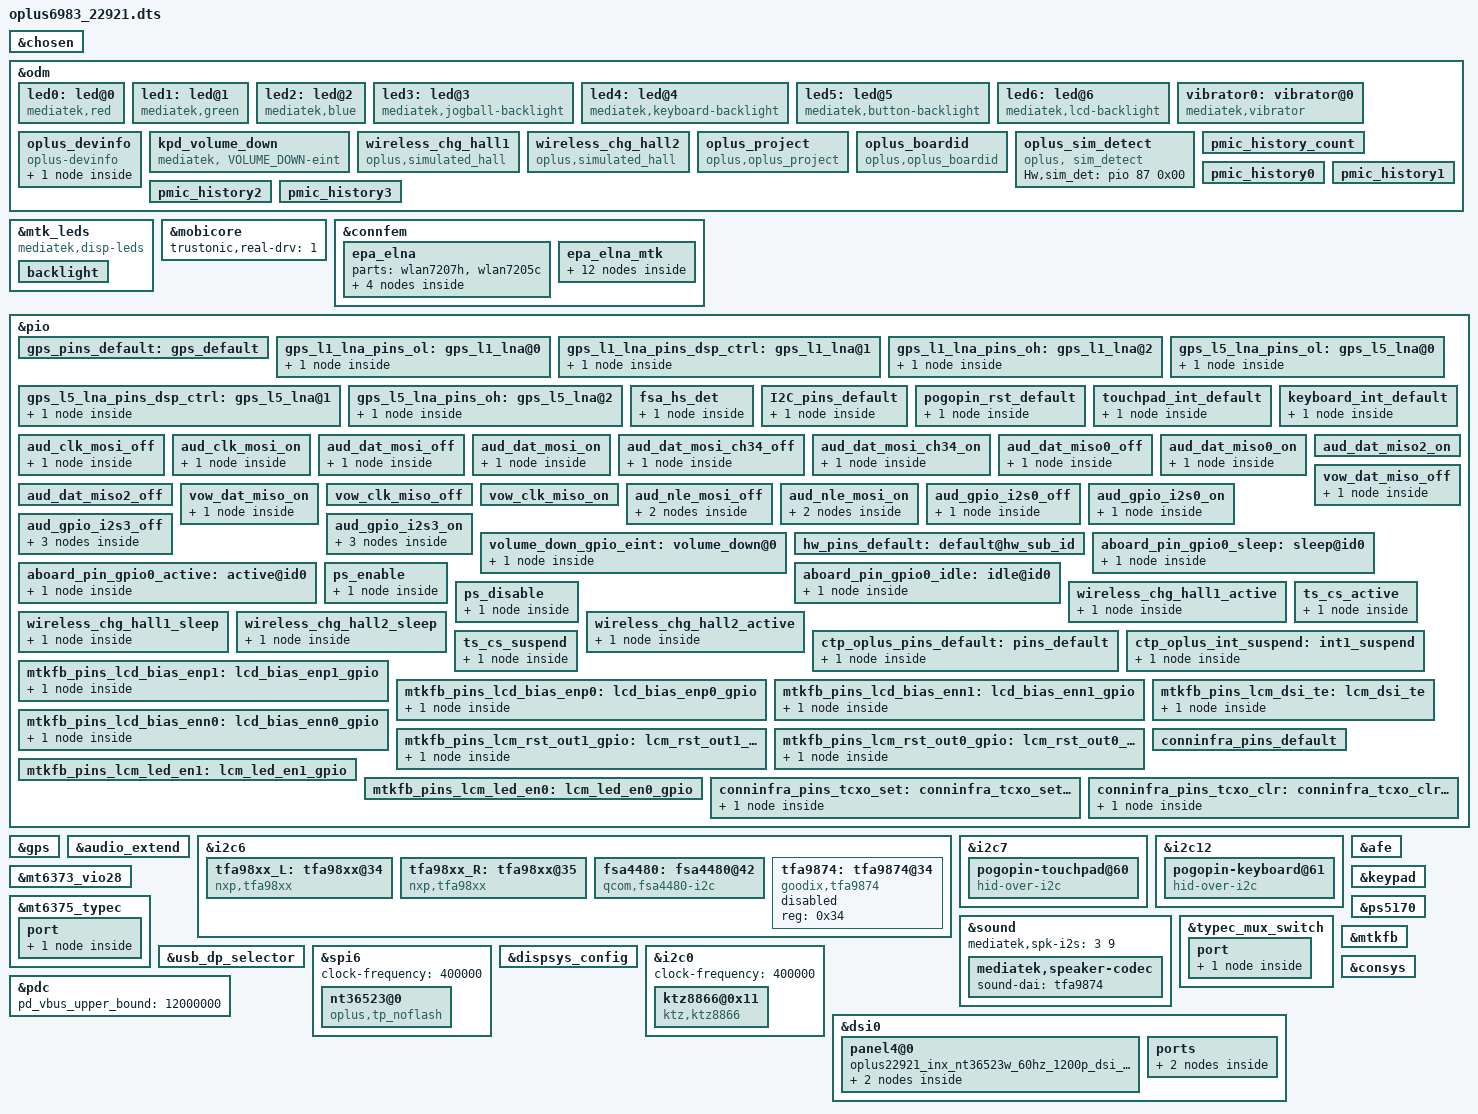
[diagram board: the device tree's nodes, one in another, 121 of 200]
// SPDX-License-Identifier: (GPL-2.0 OR MIT)
/*
 * Copyright (C) 2020 MediaTek Inc.
 */
/dts-v1/;
/plugin/;
#include <dt-bindings/interrupt-controller/arm-gic.h>
#include <dt-bindings/interrupt-controller/irq.h>
#include <dt-bindings/pinctrl/mt6983-pinfunc.h>
#include <dt-bindings/clock/mt6983-clk.h>
#include <dt-bindings/phy/phy.h>
#include "mediatek/oplus-22921-tp.dtsi"
//#ifdef OPLUS_FEATURE_CHG_BASIC
#include "mediatek/oplus_charge_22921.dtsi"
//#endif

//#ifdef OPLUS_FEATURE_SENSOR

#include "mediatek/oplus_sensor_22921.dtsi"
//#endif

//#ifdef OPLUS_FEATURE_NFC_BRINGUP
//#include "mediatek/nfc/mt6983_diting_21007_sn100.dtsi"
//#endif OPLUS_FEATURE_NFC_BRINGUP
&chosen {
	bootargs_ext = "loglevel=8 \
	androidboot.hardware=mt6983";
};

&odm {
	led0:led@0 {
		compatible = "mediatek,red";
		led_mode = <0>;
		data = <1>;
		pwm_config = <0 0 0 0 0>;
	};
	led1:led@1 {
		compatible = "mediatek,green";
		led_mode = <0>;
		data = <1>;
		pwm_config = <0 0 0 0 0>;
	};
	led2:led@2 {
		compatible = "mediatek,blue";
		led_mode = <0>;
		data = <1>;
		pwm_config = <0 0 0 0 0>;
	};
	led3:led@3 {
		compatible = "mediatek,jogball-backlight";
		led_mode = <0>;
		data = <1>;
		pwm_config = <0 0 0 0 0>;
	};
	led4:led@4 {
		compatible = "mediatek,keyboard-backlight";
		led_mode = <0>;
		data = <1>;
		pwm_config = <0 0 0 0 0>;
	};
	led5:led@5 {
		compatible = "mediatek,button-backlight";
		led_mode = <0>;
		data = <1>;
		pwm_config = <0 0 0 0 0>;
	};
	led6:led@6 {
		compatible = "mediatek,lcd-backlight";
		led_mode = <4>;
		data = <1>;
		pwm_config = <0 1 0 0 0>;
	};
	vibrator0:vibrator@0 {
		compatible = "mediatek,vibrator";
		vib_timer = <25>;
		vib_limit = <9>;
		vib_vol= <9>;
	};
};

&mtk_leds {
	compatible = "mediatek,disp-leds";
	backlight {
		label = "lcd-backlight";
		led_mode = <4>;
		max-brightness = <10239>;
		max-hw-brightness = <10239>;
		led-bits = <13>;
		};
};

/*Trustonic Mobicore real driver*/
&mobicore {
	trustonic,real-drv=<1>;
};

&connfem {
#if 1 /* Enable epa_elna node to support Wifi & BT ePA/eLNA FEM on customer load */
	epa_elna {
		parts = <&wlan7207h &wlan7205c>;

		wifi {
			flags-0 {
				/* open-loop; */
			};
		};

		bt {
			flags-0 {
				/* choose one of: epa_elna / epa / elna / bypass */
				epa_elna;
			};
		};
	};
#endif

	epa_elna_mtk {
		parts = <&nofem &nofem>,		/* [0]iPA/iLNA */
			<&wlan7207h &wlan7205c_laa>,	/* [1]ePA/eLNA - Open Loop, LAA 4x4 */
			<&wlan7207h &wlan7205c>,	/* [2]ePA/eLNA - Open Loop */
			<&wlan7207h &wlan7205c>,	/* [3]ePA/eLNA - Closed-Loop */
			<&wlan7207h &wlan7205c_laa>,	/* [4]ePA/eLNA - Closed-Loop, LAA 4x4 */
			<&wlan7207h &wlan7205c>,	/* [5]ePA/eLNA - Closed-Loop + BT Bypass */
			<&wlan7207h &wlan7205c>;	/* [6]ePA/eLNA - Open Loop + BT Bypass */

		hwid = <&pio 203 0x00>;

		wifi {
			flags-1 {
				open-loop;
				laa;
			};
			flags-2 {
				open-loop;
			};
			flags-4 {
				laa;
			};
			flags-6 {
				open-loop;
			};
		};

		bt {
			flags-1 {
				/* choose one of: epa_elna / epa / elna / bypass */
				epa_elna;
			};
			flags-2 {
				epa_elna;
			};
			flags-3 {
				epa_elna;
			};
			flags-4 {
				epa_elna;
			};
			flags-5 {
				bypass;
			};
			flags-6 {
				bypass;
			};
		};
	};
};

/* GPS GPIO standardization start */
&pio {
	gps_pins_default: gps_default {
	};

	gps_l1_lna_pins_ol: gps_l1_lna@0 {
		pins_cmd_dat {
			pinmux = <PINMUX_GPIO16__FUNC_GPIO16>;
			output-low;
		};
	};
	gps_l1_lna_pins_dsp_ctrl: gps_l1_lna@1 {
		pins_cmd_dat {
			pinmux = <PINMUX_GPIO16__FUNC_GPS_L1_ELNA_EN>;
		};
	};
	gps_l1_lna_pins_oh: gps_l1_lna@2 {
		pins_cmd_dat {
			pinmux = <PINMUX_GPIO16__FUNC_GPIO16>;
			output-high;
		};
	};

	gps_l5_lna_pins_ol: gps_l5_lna@0 {
		pins_cmd_dat {
			pinmux = <PINMUX_GPIO17__FUNC_GPIO17>;
			output-low;
		};
	};
	gps_l5_lna_pins_dsp_ctrl: gps_l5_lna@1 {
		pins_cmd_dat {
			pinmux = <PINMUX_GPIO17__FUNC_GPS_L5_ELNA_EN>;
		};
	};
	gps_l5_lna_pins_oh: gps_l5_lna@2 {
		pins_cmd_dat {
			pinmux = <PINMUX_GPIO17__FUNC_GPIO17>;
			output-high;
		};
	};
};

&gps {
	pinctrl-names = "default",
		"gps_l1_lna_disable",
		"gps_l1_lna_dsp_ctrl",
		"gps_l1_lna_enable",
		"gps_l5_lna_disable",
		"gps_l5_lna_dsp_ctrl",
		"gps_l5_lna_enable";
	pinctrl-0 = <&gps_pins_default>;
	pinctrl-1 = <&gps_l1_lna_pins_ol>;
	pinctrl-2 = <&gps_l1_lna_pins_dsp_ctrl>;
	pinctrl-3 = <&gps_l1_lna_pins_oh>;
	pinctrl-4 = <&gps_l5_lna_pins_ol>;
	pinctrl-5 = <&gps_l5_lna_pins_dsp_ctrl>;
	pinctrl-6 = <&gps_l5_lna_pins_oh>;
	status = "okay";
};
/* GPS GPIO standardization end */

//#ifdef OPLUS_ARCH_EXTENDS
&audio_extend {
	//for nxp speaker
	oplus,speaker-vendor = "nxp";
	oplus,speaker-i2s-id = <3>;
	oplus,speaker-i2s-id-in = <0>;
	oplus,speaker-codec-name = "tfa98xx.6-0034","tfa98xx.6-0035";
	oplus,speaker-codec-dai-name = "tfa98xx-aif-6-34","tfa98xx-aif-6-35";
};

&i2c6 {
	clock-frequency = <400000>;
	pinctrl-names = "default";
	pinctrl-0 = <&I2C_pins_default>;
	status = "okay";
	tfa98xx_L: tfa98xx@34 {
		compatible = "nxp,tfa98xx";
		reg = <0x34>;
		reset-gpio = <&pio 2 0>;
		tfa_min_range = <5000>;
		tfa_max_range = <8000>;
		tfa_channel = <0>;
		status = "okay";
	};

	tfa98xx_R: tfa98xx@35 {
		compatible = "nxp,tfa98xx";
		reg = <0x35>;
		reset-gpio = <&pio 1 0>;
		tfa_min_range = <5000>;
		tfa_max_range = <8000>;
		tfa_channel = <1>;
		status = "okay";
	};
};

&i2c6 {
	fsa4480: fsa4480@42 {
		compatible = "qcom,fsa4480-i2c";
		reg = <0x42>;
		fsa_audio-supply = <&mt6373_vio28>;
		pinctrl-names = "default";
		pinctrl-0 = <&fsa_hs_det>;
		fsa4480,hs-det-gpio = <&pio 98 0>;
	};
};

&pio {
	fsa_hs_det: fsa_hs_det {
		pins_cmd_dat {
			pinmux = <PINMUX_GPIO98__FUNC_GPIO98>;
			slew-rate = <1>;  /*direction 0:in, 1:out*/
			output-high;
		};
	};
};

&pio {
	I2C_pins_default: I2C_pins_default {
		pins_cmd_dat {
			pinmux = <PINMUX_GPIO49__FUNC_SCP_SCL1>,
					<PINMUX_GPIO50__FUNC_SCP_SDA1>;
			/* 0x0:75k 0x1:3k 0x2:5k 0x3:1.5k */
			/* 0x4:10k 0x5:2k 0x6:4k 0x7:1k */
			bias-pull-up = <MTK_PULL_SET_RSEL_001>;
		};
	};
};
//#endif /*OPLUS_ARCH_EXTENDS*/

&i2c6 {
	tfa9874: tfa9874@34 {
		compatible = "goodix,tfa9874";
		#sound-dai-cells = <0>;
		reg = <0x34>;
		status = "disabled";
	};
};
/*
&i2c6 {
	spk1: speaker_amp@5c {
		compatible = "richtek,rt5512";
		#sound-dai-cells = <0>;
		reg = <0x5c>;
		status = "okay";
		sound-name-prefix = "Left";
	};

	spk2: speaker_amp@5d {
		compatible = "richtek,rt5512";
		#sound-dai-cells = <0>;
		reg = <0x5d>;
		status = "okay";
		sound-name-prefix = "Right";
	};
};*/

&i2c7 {
	status = "okay";
	pogopin-touchpad@60 {
		status = "ok";
		compatible = "hid-over-i2c";
		reg = <0x60>;
		pinctrl-names = "default";
		pinctrl-0 = <&touchpad_int_default &pogopin_rst_default>;

		vdd-supply = <&mt6373_vcn33_3>;
		post-power-on-delay-ms = <100>;

		interrupt-parent = <&pio>;
		interrupts = <35 0x2008>;

		hid-descr-addr = <0x01>;
	};
};

&i2c12 {
	status = "okay";
	pogopin-keyboard@61 {
		status = "ok";
		compatible = "hid-over-i2c";
		reg = <0x61>;
		pinctrl-names = "default";
		pinctrl-0 = <&keyboard_int_default>;

		vdd-supply = <&mt6373_vcn33_3>;
		post-power-on-delay-ms = <100>;

		interrupt-parent = <&pio>;
		interrupts = <34 0x2008>;

		hid-descr-addr = <0x01>;
	};
};

&pio {
	pogopin_rst_default: pogopin_rst_default {
		pins_cmd_dat {
			pinmux = <PINMUX_GPIO203__FUNC_GPIO203>;
			output-high;
		};
	};
	touchpad_int_default: touchpad_int_default {
		pins_cmd_dat {
			pinmux = <PINMUX_GPIO35__FUNC_GPIO35>;
			input-enable;
			bias-pull-up;
		};
	};
	keyboard_int_default: keyboard_int_default {
		pins_cmd_dat {
			pinmux = <PINMUX_GPIO34__FUNC_GPIO34>;
			input-enable;
			bias-pull-up;
		};
	};
};

&sound {
	mediatek,spk-i2s = <3 9>;
	mediatek,speaker-codec {
		sound-dai = <&tfa9874>;
	};
};

/* AUDIO GPIO standardization start */
&afe {
	pinctrl-names = "aud_clk_mosi_off",
			"aud_clk_mosi_on",
			"aud_dat_mosi_off",
			"aud_dat_mosi_on",
			"aud_dat_mosi_ch34_off",
			"aud_dat_mosi_ch34_on",
			"aud_dat_miso0_off",
			"aud_dat_miso0_on",
			"aud_dat_miso2_off",
			"aud_dat_miso2_on",
			"vow_dat_miso_off",
			"vow_dat_miso_on",
			"vow_clk_miso_off",
			"vow_clk_miso_on",
			"aud_gpio_i2s0_off",
			"aud_gpio_i2s0_on",
			"aud_gpio_i2s3_off",
			"aud_gpio_i2s3_on";
	pinctrl-0 = <&aud_clk_mosi_off>;
	pinctrl-1 = <&aud_clk_mosi_on>;
	pinctrl-2 = <&aud_dat_mosi_off>;
	pinctrl-3 = <&aud_dat_mosi_on>;
	pinctrl-4 = <&aud_dat_mosi_ch34_off>;
	pinctrl-5 = <&aud_dat_mosi_ch34_on>;
	pinctrl-6 = <&aud_dat_miso0_off>;
	pinctrl-7 = <&aud_dat_miso0_on>;
	pinctrl-8 = <&aud_dat_miso2_off>;
	pinctrl-9 = <&aud_dat_miso2_on>;
	pinctrl-10 = <&vow_dat_miso_off>;
	pinctrl-11 = <&vow_dat_miso_on>;
	pinctrl-12 = <&vow_clk_miso_off>;
	pinctrl-13 = <&vow_clk_miso_on>;
	pinctrl-14 = <&aud_gpio_i2s0_off>;
	pinctrl-15 = <&aud_gpio_i2s0_on>;
	pinctrl-16 = <&aud_gpio_i2s3_off>;
	pinctrl-17 = <&aud_gpio_i2s3_on>;
};
&pio {
	aud_clk_mosi_off: aud_clk_mosi_off {
		pins_cmd0_dat {
			pinmux = <PINMUX_GPIO51__FUNC_GPIO51>;
			input-enable;
			bias-pull-down;
		};
	};
	aud_clk_mosi_on: aud_clk_mosi_on {
		pins_cmd0_dat {
			pinmux = <PINMUX_GPIO51__FUNC_AUD_CLK_MOSI>;
			input-schmitt-enable;
			bias-disable;
		};
	};
	aud_dat_mosi_off: aud_dat_mosi_off {
		pins_cmd1_dat {
			pinmux = <PINMUX_GPIO52__FUNC_GPIO52>;
			input-enable;
			bias-pull-down;
		};
	};
	aud_dat_mosi_on: aud_dat_mosi_on {
		pins_cmd1_dat {
			pinmux = <PINMUX_GPIO52__FUNC_AUD_DAT_MOSI0>;
			input-schmitt-enable;
			bias-disable;
		};
	};
	aud_dat_mosi_ch34_off: aud_dat_mosi_ch34_off {
		pins_cmd1_dat {
			pinmux = <PINMUX_GPIO53__FUNC_GPIO53>;
			input-enable;
			bias-pull-down;
		};
	};
	aud_dat_mosi_ch34_on: aud_dat_mosi_ch34_on {
		pins_cmd1_dat {
			pinmux = <PINMUX_GPIO53__FUNC_AUD_DAT_MOSI1>;
			input-schmitt-enable;
			bias-disable;
		};
	};
	aud_dat_miso0_off: aud_dat_miso0_off {
		pins_cmd1_dat {
			pinmux = <PINMUX_GPIO54__FUNC_GPIO54>;
			input-enable;
			bias-pull-down;
		};
	};
	aud_dat_miso0_on: aud_dat_miso0_on {
		pins_cmd1_dat {
			pinmux = <PINMUX_GPIO54__FUNC_AUD_DAT_MISO0>;
			input-schmitt-enable;
			bias-disable;
		};
	};
	aud_dat_miso2_off: aud_dat_miso2_off {
	/* NC GPIO0,GPIO1,GPIO2 */
	};
	aud_dat_miso2_on: aud_dat_miso2_on {
	/* NC GPIO0,GPIO1,GPIO2 */
	};
	vow_dat_miso_off: vow_dat_miso_off {
		pins_cmd1_dat {
			pinmux = <PINMUX_GPIO54__FUNC_GPIO54>;
			input-enable;
			bias-pull-down;
		};
	};
	vow_dat_miso_on: vow_dat_miso_on {
		pins_cmd1_dat {
			pinmux = <PINMUX_GPIO54__FUNC_VOW_DAT_MISO>;
			input-schmitt-enable;
			bias-disable;
		};
	};
	vow_clk_miso_off: vow_clk_miso_off {
	/* NC GPIO0,GPIO1,GPIO2 */
	};
	vow_clk_miso_on: vow_clk_miso_on {
	/* NC GPIO0,GPIO1,GPIO2 */
	};
	aud_nle_mosi_off: aud_nle_mosi_off {
		pins_cmd1_dat {
			pinmux = <PINMUX_GPIO49__FUNC_GPIO49>;
			input-enable;
			bias-pull-down;
		};
		pins_cmd2_dat {
			pinmux = <PINMUX_GPIO50__FUNC_GPIO50>;
			input-enable;
			bias-pull-down;
		};
	};
	aud_nle_mosi_on: aud_nle_mosi_on {
		pins_cmd1_dat {
			pinmux = <PINMUX_GPIO49__FUNC_AUD_NLE_MOSI0>;
			input-schmitt-enable;
			bias-disable;
		};
		pins_cmd2_dat {
			pinmux = <PINMUX_GPIO50__FUNC_AUD_NLE_MOSI1>;
			input-schmitt-enable;
			bias-disable;
		};
	};
	aud_gpio_i2s0_off: aud_gpio_i2s0_off {
		pins_cmd1_dat {
			pinmux = <PINMUX_GPIO28__FUNC_GPIO28>;
			input-enable;
			bias-pull-down;
		};
	};
	aud_gpio_i2s0_on: aud_gpio_i2s0_on {
		pins_cmd1_dat {
			pinmux = <PINMUX_GPIO28__FUNC_I2S0_DI>;
			input-schmitt-enable;
			bias-disable;
		};
	};
	aud_gpio_i2s3_off: aud_gpio_i2s3_off {
		pins_cmd1_dat {
			pinmux = <PINMUX_GPIO26__FUNC_GPIO26>;
			input-enable;
			bias-pull-down;
		};
		pins_cmd2_dat {
			pinmux = <PINMUX_GPIO27__FUNC_GPIO27>;
			input-enable;
			bias-pull-down;
		};
		pins_cmd3_dat {
			pinmux = <PINMUX_GPIO29__FUNC_GPIO29>;
			input-enable;
			bias-pull-down;
		};
	};
	aud_gpio_i2s3_on: aud_gpio_i2s3_on {
		pins_cmd1_dat {
			pinmux = <PINMUX_GPIO26__FUNC_I2S3_BCK>;
			input-schmitt-enable;
			bias-disable;
		};
		pins_cmd2_dat {
			pinmux = <PINMUX_GPIO27__FUNC_I2S3_LRCK>;
			input-schmitt-enable;
			bias-disable;
		};
		pins_cmd3_dat {
			pinmux = <PINMUX_GPIO29__FUNC_I2S3_DO>;
			input-schmitt-enable;
			bias-disable;
		};
	};
};
/* AUDIO GPIO standardization end */

&mt6373_vio28 {
       regulator-min-microvolt = <3000000>;
       regulator-max-microvolt = <3000000>;
};


&odm {
//#ifdef OPLUS_FEATURE_TP_BASIC
        oplus_devinfo:oplus_devinfo {
                compatible = "oplus-devinfo";
                pinctrl-names = "default", "aboard_gpio0_sleep", "aboard_gpio0_active", "aboard_gpio0_idle";
                pinctrl-0 = <&hw_pins_default>;
                pinctrl-1 = <&aboard_pin_gpio0_sleep>;
                pinctrl-2 = <&aboard_pin_gpio0_active>;
                pinctrl-3 = <&aboard_pin_gpio0_idle>;
                main-sub {
                        use_tristate_gpio;
                        compatible = "hw-match, main-sub";
                        aboard-gpio0 = <&pio 206 0x00>;
                        aboard-patterns = <0 1>;        /*0[high-resistance] 1[pull-down] 2[pull-up]*/
                        /*main board*/
                        match-projects = <22921 22971>;
                };
        };

	kpd_volume_down:kpd_volume_down {
                compatible = "mediatek, VOLUME_DOWN-eint";
                interrupt-parent = <&pio>;
                interrupts = <12 IRQ_TYPE_EDGE_FALLING 12 0>;
                debounce = <32000>;
                status = "okay";
        };

//#endif OPLUS_FEATURE_TP_BASIC
};

&keypad {
        keypad,volume-down = <&pio 12 0x00>;
        pinctrl-names = "volume_down_as_int";
        pinctrl-0 = <&volume_down_gpio_eint>;
        status = "okay";
};

&pio {
        volume_down_gpio_eint:volume_down@0{
                pins_cmd_dat {
                        pinmux = <PINMUX_GPIO12__FUNC_GPIO12>;
                        slew-rate = <0>;  /*direction 0:in, 1:out*/
                        input-enable;
                };
        };
};

&pio {
        hw_pins_default:default@hw_sub_id {
        };

        aboard_pin_gpio0_sleep:sleep@id0 {
                pins_cmd_dat {
                        pinmux = <PINMUX_GPIO206__FUNC_GPIO206>;
                        slew-rate = <0>;
                        bias-pull-down;
                        input-enable;
                };
        };

        aboard_pin_gpio0_active:active@id0 {
                pins_cmd_dat {
                        pinmux = <PINMUX_GPIO206__FUNC_GPIO206>;
                        slew-rate = <0>;
                        bias-pull-up;
                        input-enable;
                };
        };

        aboard_pin_gpio0_idle:idle@id0 {
                pins_cmd_dat {
                        pinmux = <PINMUX_GPIO206__FUNC_GPIO206>;
                        slew-rate = <0>;
                        bias-disable;
                        input-enable;
                };
        };
};
//#endif OPLUS_FEATURE_TP_BASIC
/* usb typec mux start */
&pio {

	ps_enable: ps_enable {
		pins_cmd_dat {
			//pinmux = <PINMUX_GPIO204__FUNC_GPIO204>;
			//output-high;
		};
	};

	ps_disable: ps_disable {
		pins_cmd_dat {
			//pinmux = <PINMUX_GPIO204__FUNC_GPIO204>;
			//output-low;
		};
	};

};
&odm {
	wireless_chg_hall1 {
		compatible = "oplus,simulated_hall";
		hall-id = <1>;
		pinctrl-names = "wireless_chg_hall1_active" , "wireless_chg_hall1_sleep";

		pinctrl-0 = <&wireless_chg_hall1_active>;
		pinctrl-1 = <&wireless_chg_hall1_sleep>;

		interrupt-parent = <&pio>;
		interrupts = <22 0x2003>;      //both rising and falling edge
		irq-gpio = <&pio 22 0x2003>;
		optional-handle-type = <1>;
		irq_active_low;
	};

	wireless_chg_hall2 {
		compatible = "oplus,simulated_hall";
		hall-id = <2>;
		pinctrl-names = "wireless_chg_hall2_active" , "wireless_chg_hall2_sleep";

		pinctrl-0 = <&wireless_chg_hall2_active>;
		pinctrl-1 = <&wireless_chg_hall2_sleep>;

		interrupt-parent = <&pio>;
		interrupts = <9 0x2003>;      //both rising and falling edge
		irq-gpio = <&pio 9 0x2003>;
		optional-handle-type = <1>;
		irq_active_low;
	};
};
&pio {
		wireless_chg_hall1_active: wireless_chg_hall1_active {
			pins_cmd_dat {
				pinmux = <PINMUX_GPIO22__FUNC_GPIO22>;
				bias-pull-up;
			};
		};
		wireless_chg_hall1_sleep: wireless_chg_hall1_sleep {
			pins_cmd_dat {
				pinmux = <PINMUX_GPIO22__FUNC_GPIO22>;
				bias-pull-up;
			};
		};
		wireless_chg_hall2_active: wireless_chg_hall2_active {
			pins_cmd_dat {
				pinmux = <PINMUX_GPIO9__FUNC_GPIO9>;
				bias-pull-up;
			};
		};
		wireless_chg_hall2_sleep: wireless_chg_hall2_sleep {

			pins_cmd_dat {
				pinmux = <PINMUX_GPIO9__FUNC_GPIO9>;
				bias-pull-up;
			};
		};
};
/*&gpio_keys {
        volumedown {
            label = "Volume_Down";
            linux,code = <114>;
            gpios = <&pio 12 1>;
            wakeup-source;
            debounce-interval = <5>;
        };
};
*/
&mt6375_typec {
	port {
		tcpc_typec_usb: endpoint@0 {
			remote-endpoint = <&ssusb_mux>;
		};
	};
};

&typec_mux_switch {
	orientation-switch;
	mode-switch;
	accessory;
	port {
		ssusb_mux: endpoint@0 {
			remote-endpoint = <&tcpc_typec_usb>;
		};
	};
};

&ps5170 {
	pinctrl-names = "enable", "disable";
	pinctrl-0 = <&ps_enable>;
	pinctrl-1 = <&ps_disable>;
	status = "okay";
};

&usb_dp_selector {
	status = "okay";
};
/* usb typec mux end */

/*add for tp bringup*/
&spi6 {
	status = "okay";
	clock-frequency = <400000>;
	nt36523@0 {
		status = "okay";
		compatible = "oplus,tp_noflash";
		reg = <0>;
		chip-num = <1>;
		chip-name = "NT36523";
		project_id = <22921>;
		firmware_name = "0X21N2NI9N19";
		spi-max-frequency = <12000000>; //4800000,9600000,15000000,19200000
		/* Interrupt && Irq-gpio */
		reset-gpio = <&pio 3 0x00>;
		interrupt-parent = <&pio>;
		interrupts = <8  0x0>;
		irq-gpio = <&pio 8 0x2002>;

		pinctrl-names = "default", "pin_cs_high","pin_cs_low";
		pinctrl-0 = <&ctp_oplus_pins_default>;
		pinctrl-1 = <&ts_cs_active>;
		pinctrl-2 = <&ts_cs_suspend &ctp_oplus_int_suspend>;

		touchpanel,max-num-support = <10>;
		touchpanel,tx-rx-num = <30 48>;
		touchpanel,panel-coords = <1200 2000>;
		touchpanel,display-coords = <1200 2000>;
		touchpanel,touchmajor-limit = <0 54>;

		touchpanel,pen-tx-rx-num = <30 48>;
		touchpanel,pen-panel-coords = <2400 4000>;
		touchpanel,pen-max-pressure = <4096>;
		touchpanel,pen-max-tilt = <60 60>;
		touchpanel,msecs-to-jiffies-time = <100>;
		tp_type = <3>;//BOE
		panel_type = <3>;

		platform_support_project = <22921 22971>;
		platform_support_project_dir = <22921 22921>;
		platform_support_commandline = "oplus22921_inx_nt36523w_60hz_1200p_dsi_vdo_lcm","oplus22921_inx_nt36523w_60hz_1200p_dsi_vdo_lcm";
		platform_support_project_commandline = "default_commandline","default_commandline";
		platform_support_project_external_name = "FA261";
		vid_len = <7>;

		incell_screen;
		//iovcc_shutdown_support;
		fw_edge_limit_support;
		black_gesture_support;
		charger_pump_support;
		headset_pump_support;
		esd_handle_support;
		black_gesture_test_support;
		game_switch_support;
		noflash_support;
		lcd_trigger_load_tp_fw_support;
		smart_gesture_support;
		pressure_report_support;
		pen_support;
		irq_need_dev_resume_ok;
		fw_update_app_support;
		health_monitor_v2_support;
		fw_update_in_probe_with_headfile;
		black_gesture_indep_support;
		touchpanel,button-type = <4>;
	};
};

&pio {
	ctp_oplus_pins_default: pins_default {
			pins_cmd0_dat {
			pinmux = <PINMUX_GPIO164__FUNC_SPI6_B_MI>,
				< PINMUX_GPIO165__FUNC_SPI6_B_CSB>,
				<PINMUX_GPIO166__FUNC_SPI6_B_MO>,
				< PINMUX_GPIO167__FUNC_SPI6_B_CLK>;
			bias-disable;
			drive-strength = <6>;
		};
	};

	ts_cs_active: ts_cs_active {
		pins_cmd_dat {
			pinmux = <PINMUX_GPIO165__FUNC_SPI6_B_CSB>;
		};
	};
	ts_cs_suspend: ts_cs_suspend {
		pins_cmd_dat {
			pinmux = <PINMUX_GPIO165__FUNC_GPIO165>;
			output-low;
		};
	};
	ctp_oplus_int_suspend: int1_suspend {
		pins_cmd_dat {
			pinmux = <PINMUX_GPIO8__FUNC_GPIO8>;
			bias-disable;
			input-enable;
		};
	};
	mtkfb_pins_lcd_bias_enp1: lcd_bias_enp1_gpio {
		pins_cmd_dat {
			pinmux = <PINMUX_GPIO84__FUNC_GPIO84>;
			slew-rate = <1>;
			output-high;
		};
	};

	mtkfb_pins_lcd_bias_enp0: lcd_bias_enp0_gpio {
		pins_cmd_dat {
			pinmux = <PINMUX_GPIO84__FUNC_GPIO84>;
			slew-rate = <1>;
			output-low;
		};
	};

	mtkfb_pins_lcd_bias_enn1: lcd_bias_enn1_gpio {
		pins_cmd_dat {
			pinmux = <PINMUX_GPIO84__FUNC_GPIO84>;
			slew-rate = <1>;
			output-high;
		};
	};

	mtkfb_pins_lcd_bias_enn0: lcd_bias_enn0_gpio {
		pins_cmd_dat {
			pinmux = <PINMUX_GPIO84__FUNC_GPIO84>;
			slew-rate = <1>;
			output-low;
		};
	};

	mtkfb_pins_lcm_rst_out1_gpio: lcm_rst_out1_gpio {
		pins_cmd_dat {
			pinmux = <PINMUX_GPIO86__FUNC_GPIO86>;
			slew-rate = <1>;
			output-high;
		};
	};

	mtkfb_pins_lcm_rst_out0_gpio: lcm_rst_out0_gpio {
		pins_cmd_dat {
			pinmux = <PINMUX_GPIO86__FUNC_GPIO86>;
			slew-rate = <1>;
			output-low;
		};
	};
	mtkfb_pins_lcm_dsi_te: lcm_dsi_te {
		pins_cmd_dat {
			pinmux = <PINMUX_GPIO85__FUNC_DSI_TE>;
		};
	};

	mtkfb_pins_lcm_led_en1: lcm_led_en1_gpio {
	};

	mtkfb_pins_lcm_led_en0: lcm_led_en0_gpio {
	};
};

&mtkfb {
	pinctrl-names = "lcd_bias_enp1_gpio", "lcd_bias_enp0_gpio",
		"lcd_bias_enn1_gpio", "lcd_bias_enn0_gpio",
		"lcm_rst_out1_gpio", "lcm_rst_out0_gpio",
		"mode_te_te", "lcm_led_en1_gpio", "lcm_led_en0_gpio";
	pinctrl-0 = <&mtkfb_pins_lcd_bias_enp1>;
	pinctrl-1 = <&mtkfb_pins_lcd_bias_enp0>;
	pinctrl-2 = <&mtkfb_pins_lcd_bias_enn1>;
	pinctrl-3 = <&mtkfb_pins_lcd_bias_enn0>;
	pinctrl-4 = <&mtkfb_pins_lcm_rst_out1_gpio>;
	pinctrl-5 = <&mtkfb_pins_lcm_rst_out0_gpio>;
	pinctrl-6 = <&mtkfb_pins_lcm_dsi_te>;
	pinctrl-7 = <&mtkfb_pins_lcm_led_en1>;
	pinctrl-8 = <&mtkfb_pins_lcm_led_en0>;

	status = "okay";
};
&dispsys_config {
	pinctrl-names =
		"lcm_rst_out1_gpio", "lcm_rst_out0_gpio",
		"mode_te_te";
	pinctrl-0 = <&mtkfb_pins_lcm_rst_out1_gpio>;
	pinctrl-1 = <&mtkfb_pins_lcm_rst_out0_gpio>;
	pinctrl-2 = <&mtkfb_pins_lcm_dsi_te>;
	status = "okay";

	helper-value = <0>, /*MTK_DRM_OPT_STAGE*/
		<1>, /*MTK_DRM_OPT_USE_CMDQ*/
		<1>, /*MTK_DRM_OPT_USE_M4U*/
		<1>, /*MTK_DRM_OPT_MMQOS_SUPPORT*/
		<1>, /*MTK_DRM_OPT_MMDVFS_SUPPORT*/
		<0>, /*MTK_DRM_OPT_SODI_SUPPORT*/
		<1>, /*MTK_DRM_OPT_IDLE_MGR*/
		<0>, /*MTK_DRM_OPT_IDLEMGR_SWTCH_DECOUPLE*/
		<1>, /*MTK_DRM_OPT_IDLEMGR_BY_REPAINT*/
		<0>, /*MTK_DRM_OPT_IDLEMGR_ENTER_ULPS*/
		<0>, /*MTK_DRM_OPT_IDLEMGR_KEEP_LP11*/
		<0>, /*MTK_DRM_OPT_DYNAMIC_RDMA_GOLDEN_SETTING*/
		<1>, /*MTK_DRM_OPT_IDLEMGR_DISABLE_ROUTINE_IRQ*/
		<0>, /*MTK_DRM_OPT_MET_LOG*/
		<1>, /*MTK_DRM_OPT_USE_PQ*/
		<1>, /*MTK_DRM_OPT_ESD_CHECK_RECOVERY*/
		<1>, /*MTK_DRM_OPT_ESD_CHECK_SWITCH*/
		<1>, /*MTK_DRM_OPT_PRESENT_FENCE*/
		<0>, /*MTK_DRM_OPT_RDMA_UNDERFLOW_AEE*/
		<0>, /*MTK_DRM_OPT_DSI_UNDERRUN_AEE*/
		<1>, /*MTK_DRM_OPT_HRT*/
		<1>, /*MTK_DRM_OPT_HRT_MODE*/
		<0>, /*MTK_DRM_OPT_DELAYED_TRIGGER*/
		<1>, /*MTK_DRM_OPT_OVL_EXT_LAYER*/
		<0>, /*MTK_DRM_OPT_AOD*/
		<1>, /*MTK_DRM_OPT_RPO*/
		<0>, /*MTK_DRM_OPT_DUAL_PIPE*/
		<0>, /*MTK_DRM_OPT_DC_BY_HRT*/
		<1>, /*MTK_DRM_OPT_OVL_WCG*/
		<0>, /*MTK_DRM_OPT_OVL_SBCH*/
		<1>, /*MTK_DRM_OPT_COMMIT_NO_WAIT_VBLANK*/
		<0>, /*MTK_DRM_OPT_MET*/
		<0>, /*MTK_DRM_OPT_REG_PARSER_RAW_DUMP*/
		<0>, /*MTK_DRM_OPT_VP_PQ*/
		<0>, /*MTK_DRM_OPT_GAME_PQ*/
		<0>, /*MTK_DRM_OPT_MMPATH*/
		<1>, /*MTK_DRM_OPT_HBM*/
		<0>, /*MTK_DRM_OPT_VDS_PATH_SWITCH*/
		<0>, /*MTK_DRM_OPT_LAYER_REC*/
		<1>, /*MTK_DRM_OPT_CLEAR_LAYER*/
		<1>, /*MTK_DRM_OPT_LFR*/
		<0>, /*MTK_DRM_OPT_SF_PF*/
		<1>, /*MTK_DRM_OPT_DYN_MIPI_CHANGE*/
		<1>, /*MTK_DRM_OPT_PRIM_DUAL_PIPE*/
		<1>, /*MTK_DRM_OPT_MSYNC2_0*/
		<1>, /*MTK_DRM_OPT_MML_PRIMARY*/
		<0>, /*MTK_DRM_OPT_MML_SUPPORT_CMD_MODE*/
		<0>, /*MTK_DRM_OPT_MML_PQ*/
		<0>, /*MTK_DRM_OPT_DUAL_TE*/
		<1>, /*MTK_DRM_OPT_RES_SWITCH*/
		<1>, /*MTK_DRM_OPT_VIRTUAL_DISP*/
		<1>; /*MTK_DRM_OPT_PRE_TE*/
};

&i2c0 {
	status = "okay";
	clock-frequency = <400000>;
	ktz8866@0x11{
		compatible = "ktz,ktz8866";
		reg = <0x11>;
		skpi_ktz8866 = <1>;
		status = "okay";
	};
};

&dsi0 {
	status = "okay";
	#address-cells = <1>;
	#size-cells = <0>;
	panel4@0 {
		compatible = "oplus22921_inx_nt36523w_60hz_1200p_dsi_vdo";
		reg = <0>;
		reset-gpios = <&pio 86 0>;
		bias_enp_en-gpios = <&pio 31 0>;
		bias_enn_en-gpios = <&pio 30 0>;
		1p8-supply = <&mt6373_vrfio18_aif>;
		pm-enable-gpios = <&pio 68 0>;
		pinctrl-names = "default";
		port {
			panel_in4: endpoint {
				remote-endpoint = <&dsi_out>;
			};
		};
	};
/*	panel2@0 {
//		compatible = "oplus21007_samsung_amb670yf01_qhd_dsi_cmd";
		reg = <1>;
		vddr1p5-enable-gpios = <&pio 148 0>;
		reset-gpios = <&pio 86 0>;
		te_switch-gpios = <&pio 24 0>;
		te_out-gpios = <&pio 36 0>;
		1p8-supply = <&mt6363_vufs18>;
		3p0-supply = <&mt6373_vmch>;
		pinctrl-names = "default";
		port {
			panel_in2: endpoint {
				remote-endpoint = <&dsi_out>;
			};
		};
	};*/
	ports {
		port {
			dsi_out: endpoint {
				remote-endpoint = <&panel_in4>;
			};
		};
	};
};

&odm {
/*OPLUS_BUG_STABILITY oppo project start */
	oplus_project:oplus_project {
		compatible = "oplus,oplus_project";
	};
/*endif*/

	oplus_boardid:oplus_boardid {
		compatible = "oplus,oplus_boardid";
		oplus_boardid,dtsino="22921";//only one u32
		oplus_boardid,pcbmask="0xffff";//all mask 0xffff
	};
};

&odm {
//#ifdef OPLUS_FEATURE_TP_BASIC
    oplus_sim_detect {
        compatible = "oplus, sim_detect";
        Hw,sim_det = <&pio 87 0x00>;
    };
//#endif /* OPLUS_FEATURE_TP_BASIC */

	pmic_history_count:pmic_history_count {
	};
	pmic_history0:pmic_history0 {
	};
	pmic_history1:pmic_history1 {
	};
	pmic_history2:pmic_history2 {
	};
	pmic_history3:pmic_history3 {
	};
};

/* CONNSYS TCXO GPIO start */
&consys {
	tcxo_support = "false";
	pinctrl-names = "default", "conninfra_tcxo_set", "conninfra_tcxo_clr";
	pinctrl-0 = <&conninfra_pins_default>;
	pinctrl-1 = <&conninfra_pins_tcxo_set>;
	pinctrl-2 = <&conninfra_pins_tcxo_clr>;
	status = "okay";
};

&pio {
	conninfra_pins_default: conninfra_pins_default {
	};
	conninfra_pins_tcxo_set: conninfra_tcxo_set@gpio {
		pins_cmd_dat {
			pinmux = <PINMUX_GPIO159__FUNC_CONN_TCXOENA_REQ>;
		};
	};
	conninfra_pins_tcxo_clr: conninfra_tcxo_clr@gpio {
		pins_cmd_dat {
			pinmux = <PINMUX_GPIO159__FUNC_GPIO159>;
		};
	};
};
/* CONNSYS TCXO GPIO end */

&pdc {
	pd_vbus_upper_bound = <12000000>;
};

#include <oplus6983_22921/cust.dtsi>
//#include "mediatek/cust_mt6983_camera_v4l2.dtsi"
#include "mediatek/cust_mt6983_aries_camera_v4l2.dtsi"
#include "mediatek/cust_mt6983_aries_cam_thermal.dtsi"
